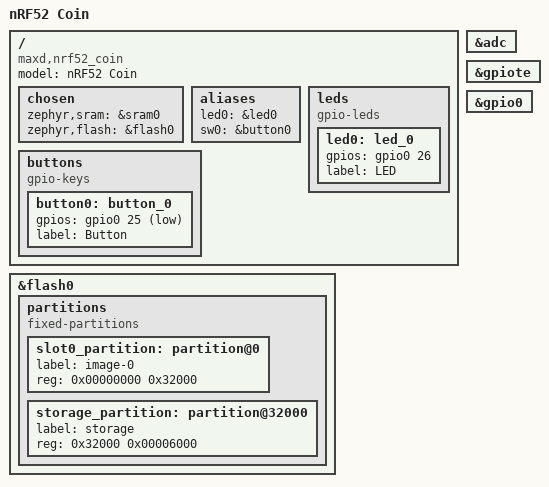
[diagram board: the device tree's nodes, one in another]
/*
 * Copyright (c) Fuck Licenses Corp.
 *
 * SPDX-License-Identifier: Apache-2.0
 */

/dts-v1/;
#include <nordic/nrf52832_qfaa.dtsi>

/ {
	model = "nRF52 Coin";
	compatible = "maxd,nrf52_coin", "nordic,nrf52832-qfaa",
		     "nordic,nrf52832";

	chosen {
		zephyr,sram = &sram0;
		zephyr,flash = &flash0;
	};

	/* These aliases are provided for compatibility with samples */
	aliases {
		led0 = &led0;
		sw0 = &button0;
	};

	leds {
		compatible = "gpio-leds";
		led0: led_0 {
			gpios = <&gpio0 26 0>;
			label = "LED";
		};
	};

	buttons {
		compatible = "gpio-keys";
		button0: button_0 {
			gpios = <&gpio0 25 (GPIO_PUD_PULL_UP |
					    GPIO_INT_ACTIVE_LOW)>;
			label = "Button";
		};
	};
};

&adc {
	status ="okay";
};

&gpiote {
	status ="okay";
};

&gpio0 {
	status ="okay";
};

&flash0 {
	/*
	 * For more information, see:
	 * http://docs.zephyrproject.org/latest/guides/dts/index.html#flash-partitions
	 */
	partitions {
		compatible = "fixed-partitions";
		#address-cells = <1>;
		#size-cells = <1>;
		slot0_partition: partition@0 {
			label = "image-0";
			reg = <0x00000000 0x32000>;
		};

		storage_partition: partition@32000 {
			label = "storage";
			reg = <0x32000 0x00006000>;
		};
	};
};
